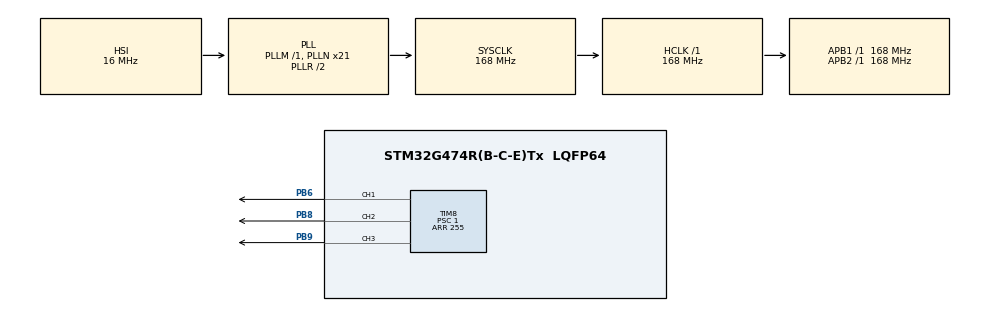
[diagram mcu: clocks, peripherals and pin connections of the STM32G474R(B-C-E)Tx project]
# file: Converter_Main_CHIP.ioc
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Mcu.Family=STM32G4
Mcu.Name=STM32G474R(B-C-E)Tx
Mcu.Package=LQFP64
NVIC.PriorityGroup=NVIC_PRIORITYGROUP_4
PA13.Mode=Trace_Asynchronous_SW
PA13.Signal=SYS_JTMS-SWDIO
PA14.Mode=Trace_Asynchronous_SW
PA14.Signal=SYS_JTCK-SWCLK
PB3.Mode=Trace_Asynchronous_SW
PB3.Signal=SYS_JTDO-SWO
PB6.Signal=S_TIM8_CH1
PB8-BOOT0.Signal=S_TIM8_CH2
PB9.Signal=S_TIM8_CH3
PC14-OSC32_IN.Mode=LSE-External-Oscillator
PC14-OSC32_IN.Signal=RCC_OSC32_IN
PC15-OSC32_OUT.Mode=LSE-External-Oscillator
PC15-OSC32_OUT.Signal=RCC_OSC32_OUT
ProjectManager.HeapSize=0x200
ProjectManager.StackSize=0x400
ProjectManager.TargetToolchain=STM32CubeIDE
RCC.ADC12Freq_Value=168000000
RCC.ADC345Freq_Value=168000000
RCC.AHBFreq_Value=168000000
RCC.APB1Freq_Value=168000000
RCC.APB1TimFreq_Value=168000000
RCC.APB2Freq_Value=168000000
RCC.APB2TimFreq_Value=168000000
RCC.CortexFreq_Value=168000000
RCC.EXTERNAL_CLOCK_VALUE=12288000
RCC.HCLKFreq_Value=168000000
RCC.HSE_VALUE=8000000
RCC.HSI48_VALUE=48000000
RCC.HSI_VALUE=16000000
RCC.PLLN=21
RCC.SYSCLKFreq_VALUE=168000000
RCC.SYSCLKSource=RCC_SYSCLKSOURCE_PLLCLK
RCC.USBFreq_Value=168000000
RCC.VCOOutputFreq_Value=336000000
SH.S_TIM8_CH1.0=TIM8_CH1,PWM Generation1 CH1
SH.S_TIM8_CH2.0=TIM8_CH2,PWM Generation2 CH2
SH.S_TIM8_CH3.0=TIM8_CH3,PWM Generation3 CH3
TIM8.AutoReloadPreload=TIM_AUTORELOAD_PRELOAD_ENABLE
TIM8.Channel-PWM\ Generation1\ CH1=TIM_CHANNEL_1
TIM8.Channel-PWM\ Generation2\ CH2=TIM_CHANNEL_2
TIM8.Channel-PWM\ Generation3\ CH3=TIM_CHANNEL_3
TIM8.PeriodNoDither=255
TIM8.Prescaler=1
VP_SYS_VS_DBSignals.Mode=DisableDeadBatterySignals
VP_TIM8_VS_ClockSourceINT.Mode=Internal
board=custom

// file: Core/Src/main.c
/* USER CODE BEGIN Header */
/**
  ******************************************************************************
  * @file           : main.c
  * @brief          : Main program body
  ******************************************************************************
  * @attention
  *
  * Copyright (c) 2025 STMicroelectronics.
  * All rights reserved.
  *
  * This software is licensed under terms that can be found in the LICENSE file
  * in the root directory of this software component.
  * If no LICENSE file comes with this software, it is provided AS-IS.
  *
  ******************************************************************************
  */
/* USER CODE END Header */
#include "main.h"

/* USER CODE BEGIN Includes */
#include "SPI/SPI.h"
#include "SPI/configuration.h"
#include <stdlib.h>
#include <stdio.h>

/* USER CODE END Includes */

TIM_HandleTypeDef htim8;

void SystemClock_Config(void);
static void MX_GPIO_Init(void);
static void MX_TIM8_Init(void);
/* USER CODE BEGIN PFP */
int _write(int file, char *ptr, int len)
{
  for (int i = 0; i < len; i++) {
    ITM_SendChar(*ptr++);
  }
  return len;
}
/* USER CODE END PFP */

int main(void)
{

  /* USER CODE BEGIN 1 */
	gpio_cnfg();
  /* USER CODE END 1 */

  /* MCU Configuration--------------------------------------------------------*/

  /* Reset of all peripherals, Initializes the Flash interface and the Systick. */
  HAL_Init();

  /* Configure the system clock */
  SystemClock_Config();

  /* Initialize all configured peripherals */
  MX_GPIO_Init();
  MX_TIM8_Init();

  /* Infinite loop */
  /* USER CODE BEGIN WHILE */
    gpio_cnfg_direct();
    spi_cnfg();
    config_CS();
    uint16_t* data = (uint16_t*)malloc(sizeof(uint16_t) * 1);
    uint16_t* receive = (uint16_t*)malloc(sizeof(uint16_t) * 1);
    receive[0] = 255;
    data[0] = 2048;
    TIM8->CCR1 = 255/2;
    TIM8->CCR2 = 255/2;
    TIM8->CCR3 = 255/2;
    HAL_TIM_PWM_Start(&htim8, TIM_CHANNEL_1);
    HAL_TIM_PWM_Start(&htim8, TIM_CHANNEL_3);
    HAL_TIM_PWM_Start(&htim8, TIM_CHANNEL_2);
    Sensor a;
		a.address = 2048;
		a.data = 255;
		a.pin = 12;
		a.id = 1;
    Sensor b;
       b.address = 0;
       b.data = 255;
       b.pin = 12;
       b.id = 2;
   Sensor c;
		c.address = 2048;
		c.data = 255;
		c.pin = 11;
		c.id = 3;
   Sensor d;
	  d.address = 0;
	  d.data = 255;
	  d.pin = 11;
	  d.id = 4;

	 // comnet.id_prev = 1;
	 // comnet.busy = 0;
	  //GPIOB->BSRR |= ((uint16_t)1 << (11));
	  //GPIOB->BSRR |= ((uint16_t)1 << (12));
	  comnet.id = 1;
	  comnet.busy = 0;
	  comnet.id_prev = 1;
;
    while (1)
    {

    	if(!comnet.busy){
    		comnet.id = (comnet.id_prev == 5) ? 1 : comnet.id_prev;
    		comnet.id_prev = comnet.id;
    	}
    	SPI_INIT_TRANSFER(&a);
    	SPI_INIT_TRANSFER(&b);
    	SPI_INIT_TRANSFER(&c);
    	SPI_INIT_TRANSFER(&d);
//    	printf(" Data : %.2f", (float)a.data / 90.0f);
//    	printf(" | %.2f ", (float)b.data / 39.0f);
//    	printf(" | %.2f ", (float)c.data / 39.0f);
//    	printf(" | %.2f \n", (float)d.data / 39.0f);
  	  //HAL_Delay(1);
  	 // float a = (float)receive[0];// / (float)4096;
  	  //printf("%.2f", (float)receive[0]); /// 37.87f
  	  //printf("\n");

  	 // HAL_Delay(10);
  //	  SPI2->CR1 |= (1 << 6);
  //	  while (!(SPI2->SR & (1 << 1)));
  //	  SPI2->DR = 0xAA;
  //	  while (SPI2->SR & (1 << 7));
  //	  SPI2->CR1 &= ~(1 << 6);
  	 // GPIOB->MODER &= 0;
  	  //transfer_function(7);+
    /* USER CODE END WHILE */

    }
}

void SystemClock_Config(void)
{
  RCC_OscInitTypeDef RCC_OscInitStruct = {0};
  RCC_ClkInitTypeDef RCC_ClkInitStruct = {0};

  /** Configure the main internal regulator output voltage
  */
  HAL_PWREx_ControlVoltageScaling(PWR_REGULATOR_VOLTAGE_SCALE1_BOOST);

  /** Initializes the RCC Oscillators according to the specified parameters
  * in the RCC_OscInitTypeDef structure.
  */
  RCC_OscInitStruct.OscillatorType = RCC_OSCILLATORTYPE_HSI;
  RCC_OscInitStruct.HSIState = RCC_HSI_ON;
  RCC_OscInitStruct.HSICalibrationValue = RCC_HSICALIBRATION_DEFAULT;
  RCC_OscInitStruct.PLL.PLLState = RCC_PLL_ON;
  RCC_OscInitStruct.PLL.PLLSource = RCC_PLLSOURCE_HSI;
  RCC_OscInitStruct.PLL.PLLM = RCC_PLLM_DIV1;
  RCC_OscInitStruct.PLL.PLLN = 21;
  RCC_OscInitStruct.PLL.PLLP = RCC_PLLP_DIV2;
  RCC_OscInitStruct.PLL.PLLQ = RCC_PLLQ_DIV2;
  RCC_OscInitStruct.PLL.PLLR = RCC_PLLR_DIV2;
  if (HAL_RCC_OscConfig(&RCC_OscInitStruct) != HAL_OK)
  {
    Error_Handler();
  }

  /** Initializes the CPU, AHB and APB buses clocks
  */
  RCC_ClkInitStruct.ClockType = RCC_CLOCKTYPE_HCLK|RCC_CLOCKTYPE_SYSCLK
                              |RCC_CLOCKTYPE_PCLK1|RCC_CLOCKTYPE_PCLK2;
  RCC_ClkInitStruct.SYSCLKSource = RCC_SYSCLKSOURCE_PLLCLK;
  RCC_ClkInitStruct.AHBCLKDivider = RCC_SYSCLK_DIV1;
  RCC_ClkInitStruct.APB1CLKDivider = RCC_HCLK_DIV1;
  RCC_ClkInitStruct.APB2CLKDivider = RCC_HCLK_DIV1;

  if (HAL_RCC_ClockConfig(&RCC_ClkInitStruct, FLASH_LATENCY_4) != HAL_OK)
  {
    Error_Handler();
  }
}

static void MX_TIM8_Init(void)
{

  TIM_ClockConfigTypeDef sClockSourceConfig = {0};
  TIM_MasterConfigTypeDef sMasterConfig = {0};
  TIM_OC_InitTypeDef sConfigOC = {0};
  TIM_BreakDeadTimeConfigTypeDef sBreakDeadTimeConfig = {0};

  htim8.Instance = TIM8;
  htim8.Init.Prescaler = 1;
  htim8.Init.CounterMode = TIM_COUNTERMODE_UP;
  htim8.Init.Period = 255;
  htim8.Init.ClockDivision = TIM_CLOCKDIVISION_DIV1;
  htim8.Init.RepetitionCounter = 0;
  htim8.Init.AutoReloadPreload = TIM_AUTORELOAD_PRELOAD_ENABLE;
  if (HAL_TIM_Base_Init(&htim8) != HAL_OK)
  {
    Error_Handler();
  }
  sClockSourceConfig.ClockSource = TIM_CLOCKSOURCE_INTERNAL;
  if (HAL_TIM_ConfigClockSource(&htim8, &sClockSourceConfig) != HAL_OK)
  {
    Error_Handler();
  }
  if (HAL_TIM_PWM_Init(&htim8) != HAL_OK)
  {
    Error_Handler();
  }
  sMasterConfig.MasterOutputTrigger = TIM_TRGO_RESET;
  sMasterConfig.MasterOutputTrigger2 = TIM_TRGO2_RESET;
  sMasterConfig.MasterSlaveMode = TIM_MASTERSLAVEMODE_DISABLE;
  if (HAL_TIMEx_MasterConfigSynchronization(&htim8, &sMasterConfig) != HAL_OK)
  {
    Error_Handler();
  }
  sConfigOC.OCMode = TIM_OCMODE_PWM1;
  sConfigOC.Pulse = 0;
  sConfigOC.OCPolarity = TIM_OCPOLARITY_HIGH;
  sConfigOC.OCNPolarity = TIM_OCNPOLARITY_HIGH;
  sConfigOC.OCFastMode = TIM_OCFAST_DISABLE;
  sConfigOC.OCIdleState = TIM_OCIDLESTATE_RESET;
  sConfigOC.OCNIdleState = TIM_OCNIDLESTATE_RESET;
  if (HAL_TIM_PWM_ConfigChannel(&htim8, &sConfigOC, TIM_CHANNEL_1) != HAL_OK)
  {
    Error_Handler();
  }
  if (HAL_TIM_PWM_ConfigChannel(&htim8, &sConfigOC, TIM_CHANNEL_2) != HAL_OK)
  {
    Error_Handler();
  }
  if (HAL_TIM_PWM_ConfigChannel(&htim8, &sConfigOC, TIM_CHANNEL_3) != HAL_OK)
  {
    Error_Handler();
  }
  sBreakDeadTimeConfig.OffStateRunMode = TIM_OSSR_DISABLE;
  sBreakDeadTimeConfig.OffStateIDLEMode = TIM_OSSI_DISABLE;
  sBreakDeadTimeConfig.LockLevel = TIM_LOCKLEVEL_OFF;
  sBreakDeadTimeConfig.DeadTime = 0;
  sBreakDeadTimeConfig.BreakState = TIM_BREAK_DISABLE;
  sBreakDeadTimeConfig.BreakPolarity = TIM_BREAKPOLARITY_HIGH;
  sBreakDeadTimeConfig.BreakFilter = 0;
  sBreakDeadTimeConfig.BreakAFMode = TIM_BREAK_AFMODE_INPUT;
  sBreakDeadTimeConfig.Break2State = TIM_BREAK2_DISABLE;
  sBreakDeadTimeConfig.Break2Polarity = TIM_BREAK2POLARITY_HIGH;
  sBreakDeadTimeConfig.Break2Filter = 0;
  sBreakDeadTimeConfig.Break2AFMode = TIM_BREAK_AFMODE_INPUT;
  sBreakDeadTimeConfig.AutomaticOutput = TIM_AUTOMATICOUTPUT_DISABLE;
  if (HAL_TIMEx_ConfigBreakDeadTime(&htim8, &sBreakDeadTimeConfig) != HAL_OK)
  {
    Error_Handler();
  }
  HAL_TIM_MspPostInit(&htim8);

}

static void MX_GPIO_Init(void)
{

  /* GPIO Ports Clock Enable */
  __HAL_RCC_GPIOC_CLK_ENABLE();
  __HAL_RCC_GPIOA_CLK_ENABLE();
  __HAL_RCC_GPIOB_CLK_ENABLE();

}

void Error_Handler(void)
{
  __disable_irq();
  while (1)
  {
  }
}
